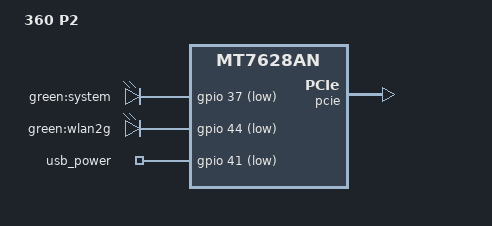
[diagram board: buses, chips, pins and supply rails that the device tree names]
#include "mt7628an_hiwifi_hc5x61a.dtsi"

/ {
	compatible = "360,p2", "mediatek,mt7628an-soc";
	model = "360 P2";

	leds {
		compatible = "gpio-leds";

		led_system: system {
			label = "green:system";
			gpios = <&gpio 37 GPIO_ACTIVE_LOW>;
		};

		wlan2g {
			label = "green:wlan2g";
			gpios = <&gpio 44 GPIO_ACTIVE_LOW>;
			linux,default-trigger = "phy0tpt";
		};
	};

	gpio_export {
		compatible = "gpio-export";
		#size-cells = <0>;

		usb_power {
			gpio-export,name = "usb_power";
			gpio-export,output = <0>;
			gpios = <&gpio 41 GPIO_ACTIVE_LOW>;
		};
	};
};

&state_default {
	gpio {
		groups = "refclk", "wdt", "wled_an";
		function = "gpio";
	};
};

&pcie {
	status = "okay";
};

&pcie0 {
	wifi@0,0 {
		reg = <0x0000 0 0 0 0>;
		mediatek,mtd-eeprom = <&factory 0x8000>;
		mtd-mac-address = <&factory 0x2e>;
		ieee80211-freq-limit = <5000000 6000000>;

		led {
			led-sources = <2>;
			led-active-low;
		};
	};
};
